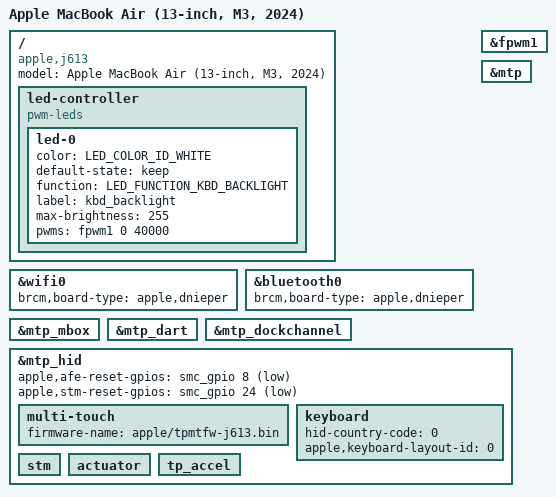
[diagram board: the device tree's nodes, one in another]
// SPDX-License-Identifier: GPL-2.0+ OR MIT
/*
 * Apple MacBook Air (13-inch, M3, 2024)
 *
 * target-type: J613
 *
 * Copyright The Asahi Linux Contributors
 */

/dts-v1/;

#include "t8122.dtsi"
#include "t8122-jxxx.dtsi"
#include <dt-bindings/leds/common.h>

/ {
	compatible = "apple,j613", "apple,t8122", "apple,arm-platform";
	model = "Apple MacBook Air (13-inch, M3, 2024)";

	led-controller {
		compatible = "pwm-leds";

		led-0 {
			color = <LED_COLOR_ID_WHITE>;
			default-state = "keep";
			function = LED_FUNCTION_KBD_BACKLIGHT;
			label = "kbd_backlight";
			max-brightness = <255>;
			pwms = <&fpwm1 0 40000>;
		};
	};
};

&wifi0 {
	brcm,board-type = "apple,dnieper";
};

&bluetooth0 {
	brcm,board-type = "apple,dnieper";
};

&fpwm1 {
	status = "okay";
};

&mtp {
	status = "okay";
};

&mtp_mbox {
	status = "okay";
};

&mtp_dart {
	status = "okay";
};

&mtp_dockchannel {
	status = "okay";
};

&mtp_hid {
	apple,afe-reset-gpios = <&smc_gpio 8 GPIO_ACTIVE_LOW>;
	apple,stm-reset-gpios = <&smc_gpio 24 GPIO_ACTIVE_LOW>;

	multi-touch {
		firmware-name = "apple/tpmtfw-j613.bin";
	};

	keyboard: keyboard {
		hid-country-code = <0>;
		apple,keyboard-layout-id = <0>;
	};

	stm {
	};

	actuator {
	};

	tp_accel {
	};
};

#include "hwmon-laptop.dtsi"
